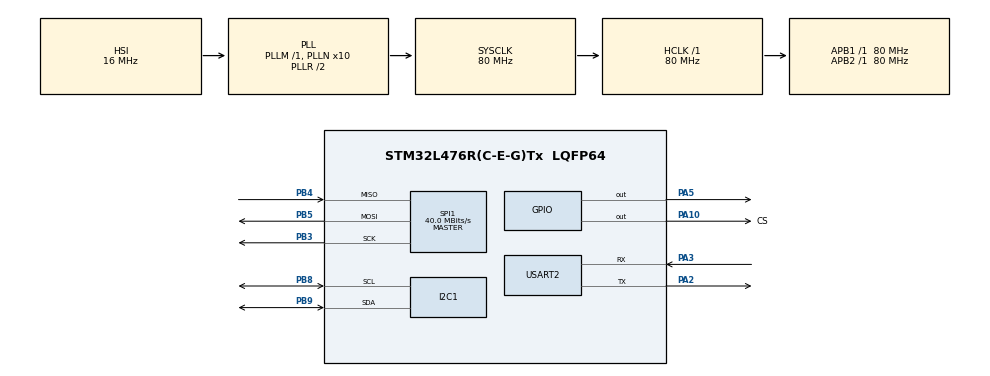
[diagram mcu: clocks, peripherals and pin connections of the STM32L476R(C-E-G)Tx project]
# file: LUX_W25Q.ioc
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Dma.I2C1_RX.0.Direction=DMA_PERIPH_TO_MEMORY
Dma.I2C1_RX.0.Instance=DMA1_Channel7
Dma.I2C1_RX.0.MemDataAlignment=DMA_MDATAALIGN_BYTE
Dma.I2C1_RX.0.MemInc=DMA_MINC_ENABLE
Dma.I2C1_RX.0.Mode=DMA_NORMAL
Dma.I2C1_RX.0.PeriphDataAlignment=DMA_PDATAALIGN_BYTE
Dma.I2C1_RX.0.PeriphInc=DMA_PINC_DISABLE
Dma.I2C1_RX.0.Priority=DMA_PRIORITY_LOW
Dma.I2C1_TX.1.Direction=DMA_MEMORY_TO_PERIPH
Dma.I2C1_TX.1.Instance=DMA1_Channel6
Dma.I2C1_TX.1.MemDataAlignment=DMA_MDATAALIGN_BYTE
Dma.I2C1_TX.1.MemInc=DMA_MINC_ENABLE
Dma.I2C1_TX.1.Mode=DMA_NORMAL
Dma.I2C1_TX.1.PeriphDataAlignment=DMA_PDATAALIGN_BYTE
Dma.I2C1_TX.1.PeriphInc=DMA_PINC_DISABLE
Dma.I2C1_TX.1.Priority=DMA_PRIORITY_LOW
Dma.Request0=I2C1_RX
Dma.Request1=I2C1_TX
I2C1.Timing=0x10909CEC
Mcu.Family=STM32L4
Mcu.Name=STM32L476R(C-E-G)Tx
Mcu.Package=LQFP64
NVIC.DMA1_Channel6_IRQn=true\:0\:0\:false\:false\:true\:false\:true
NVIC.DMA1_Channel7_IRQn=true\:0\:0\:false\:false\:true\:false\:true
NVIC.I2C1_ER_IRQn=true\:0\:0\:false\:false\:true\:true\:true
NVIC.I2C1_EV_IRQn=true\:0\:0\:false\:false\:true\:true\:true
NVIC.PriorityGroup=NVIC_PRIORITYGROUP_4
PA10.GPIO_Label=CS
PA10.Signal=GPIO_Output
PA2.Mode=Asynchronous
PA2.Signal=USART2_TX
PA3.Mode=Asynchronous
PA3.Signal=USART2_RX
PA5.Signal=GPIO_Output
PB3\ (JTDO-TRACESWO).Mode=Full_Duplex_Master
PB3\ (JTDO-TRACESWO).Signal=SPI1_SCK
PB4\ (NJTRST).Mode=Full_Duplex_Master
PB4\ (NJTRST).Signal=SPI1_MISO
PB5.Mode=Full_Duplex_Master
PB5.Signal=SPI1_MOSI
PB8.Mode=I2C
PB8.Signal=I2C1_SCL
PB9.Mode=I2C
PB9.Signal=I2C1_SDA
ProjectManager.HeapSize=0x200
ProjectManager.StackSize=0x400
ProjectManager.TargetToolchain=SW4STM32
RCC.ADCFreq_Value=64000000
RCC.AHBFreq_Value=80000000
RCC.APB1Freq_Value=80000000
RCC.APB1TimFreq_Value=80000000
RCC.APB2Freq_Value=80000000
RCC.APB2TimFreq_Value=80000000
RCC.CortexFreq_Value=80000000
RCC.HCLKFreq_Value=80000000
RCC.HSE_VALUE=8000000
RCC.HSI_VALUE=16000000
RCC.LSE_VALUE=32768
RCC.MSI_VALUE=4000000
RCC.PLLN=10
RCC.PLLSourceVirtual=RCC_PLLSOURCE_HSI
RCC.PREFETCH_ENABLE=1
RCC.SYSCLKFreq_VALUE=80000000
RCC.SYSCLKSource=RCC_SYSCLKSOURCE_PLLCLK
RCC.USBFreq_Value=64000000
RCC.VCOOutputFreq_Value=160000000
SPI1.CalculateBaudRate=40.0 MBits/s
SPI1.DataSize=SPI_DATASIZE_8BIT
SPI1.Direction=SPI_DIRECTION_2LINES
SPI1.Mode=SPI_MODE_MASTER
SPI1.VirtualType=VM_MASTER
USART2.VirtualMode-Asynchronous=VM_ASYNC
board=NUCLEO-L476RG

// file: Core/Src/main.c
/* USER CODE BEGIN Header */
/**
  ******************************************************************************
  * @file           : main.c
  * @brief          : Main program body
  ******************************************************************************
  * @attention
  *
  * <h2><center>&copy; Copyright (c) 2021 STMicroelectronics.
  * All rights reserved.</center></h2>
  *
  * This software component is licensed by ST under BSD 3-Clause license,
  * the "License"; You may not use this file except in compliance with the
  * License. You may obtain a copy of the License at:
  *                        opensource.org/licenses/BSD-3-Clause
  *
  ******************************************************************************
  */
/* USER CODE END Header */
#include "main.h"

/* USER CODE BEGIN Includes */
#include "W25Q.h"
#include "LUX.h"
/* USER CODE END Includes */

I2C_HandleTypeDef hi2c1;
DMA_HandleTypeDef hdma_i2c1_rx;
DMA_HandleTypeDef hdma_i2c1_tx;

SPI_HandleTypeDef hspi1;

UART_HandleTypeDef huart2;

void SystemClock_Config(void);
static void MX_GPIO_Init(void);
static void MX_DMA_Init(void);
static void MX_I2C1_Init(void);
static void MX_SPI1_Init(void);
static void MX_USART2_UART_Init(void);

int main(void)
{

  /* MCU Configuration--------------------------------------------------------*/

  /* Reset of all peripherals, Initializes the Flash interface and the Systick. */
  HAL_Init();

  /* Configure the system clock */
  SystemClock_Config();

  /* Initialize all configured peripherals */
  MX_GPIO_Init();
  MX_DMA_Init();
  MX_I2C1_Init();
  MX_SPI1_Init();
  MX_USART2_UART_Init();
  /* USER CODE BEGIN 2 */
  W25_Ini();
  //Erase();

  /* USER CODE END 2 */
  W25_Display();
  /* Infinite loop */
  while (1)
  {
	 // Get_I2C_Value();

  }
}

void SystemClock_Config(void)
{
  RCC_OscInitTypeDef RCC_OscInitStruct = {0};
  RCC_ClkInitTypeDef RCC_ClkInitStruct = {0};
  RCC_PeriphCLKInitTypeDef PeriphClkInit = {0};

  /** Initializes the RCC Oscillators according to the specified parameters
  * in the RCC_OscInitTypeDef structure.
  */
  RCC_OscInitStruct.OscillatorType = RCC_OSCILLATORTYPE_HSI;
  RCC_OscInitStruct.HSIState = RCC_HSI_ON;
  RCC_OscInitStruct.HSICalibrationValue = RCC_HSICALIBRATION_DEFAULT;
  RCC_OscInitStruct.PLL.PLLState = RCC_PLL_ON;
  RCC_OscInitStruct.PLL.PLLSource = RCC_PLLSOURCE_HSI;
  RCC_OscInitStruct.PLL.PLLM = 1;
  RCC_OscInitStruct.PLL.PLLN = 10;
  RCC_OscInitStruct.PLL.PLLP = RCC_PLLP_DIV7;
  RCC_OscInitStruct.PLL.PLLQ = RCC_PLLQ_DIV2;
  RCC_OscInitStruct.PLL.PLLR = RCC_PLLR_DIV2;
  if (HAL_RCC_OscConfig(&RCC_OscInitStruct) != HAL_OK)
  {
    Error_Handler();
  }
  /** Initializes the CPU, AHB and APB buses clocks
  */
  RCC_ClkInitStruct.ClockType = RCC_CLOCKTYPE_HCLK|RCC_CLOCKTYPE_SYSCLK
                              |RCC_CLOCKTYPE_PCLK1|RCC_CLOCKTYPE_PCLK2;
  RCC_ClkInitStruct.SYSCLKSource = RCC_SYSCLKSOURCE_PLLCLK;
  RCC_ClkInitStruct.AHBCLKDivider = RCC_SYSCLK_DIV1;
  RCC_ClkInitStruct.APB1CLKDivider = RCC_HCLK_DIV1;
  RCC_ClkInitStruct.APB2CLKDivider = RCC_HCLK_DIV1;

  if (HAL_RCC_ClockConfig(&RCC_ClkInitStruct, FLASH_LATENCY_4) != HAL_OK)
  {
    Error_Handler();
  }
  PeriphClkInit.PeriphClockSelection = RCC_PERIPHCLK_USART2|RCC_PERIPHCLK_I2C1;
  PeriphClkInit.Usart2ClockSelection = RCC_USART2CLKSOURCE_PCLK1;
  PeriphClkInit.I2c1ClockSelection = RCC_I2C1CLKSOURCE_PCLK1;
  if (HAL_RCCEx_PeriphCLKConfig(&PeriphClkInit) != HAL_OK)
  {
    Error_Handler();
  }
  /** Configure the main internal regulator output voltage
  */
  if (HAL_PWREx_ControlVoltageScaling(PWR_REGULATOR_VOLTAGE_SCALE1) != HAL_OK)
  {
    Error_Handler();
  }
}

static void MX_I2C1_Init(void)
{

  hi2c1.Instance = I2C1;
  hi2c1.Init.Timing = 0x10909CEC;
  hi2c1.Init.OwnAddress1 = 0;
  hi2c1.Init.AddressingMode = I2C_ADDRESSINGMODE_7BIT;
  hi2c1.Init.DualAddressMode = I2C_DUALADDRESS_DISABLE;
  hi2c1.Init.OwnAddress2 = 0;
  hi2c1.Init.OwnAddress2Masks = I2C_OA2_NOMASK;
  hi2c1.Init.GeneralCallMode = I2C_GENERALCALL_DISABLE;
  hi2c1.Init.NoStretchMode = I2C_NOSTRETCH_DISABLE;
  if (HAL_I2C_Init(&hi2c1) != HAL_OK)
  {
    Error_Handler();
  }
  /** Configure Analogue filter
  */
  if (HAL_I2CEx_ConfigAnalogFilter(&hi2c1, I2C_ANALOGFILTER_ENABLE) != HAL_OK)
  {
    Error_Handler();
  }
  /** Configure Digital filter
  */
  if (HAL_I2CEx_ConfigDigitalFilter(&hi2c1, 0) != HAL_OK)
  {
    Error_Handler();
  }

}

static void MX_SPI1_Init(void)
{

  /* SPI1 parameter configuration*/
  hspi1.Instance = SPI1;
  hspi1.Init.Mode = SPI_MODE_MASTER;
  hspi1.Init.Direction = SPI_DIRECTION_2LINES;
  hspi1.Init.DataSize = SPI_DATASIZE_8BIT;
  hspi1.Init.CLKPolarity = SPI_POLARITY_LOW;
  hspi1.Init.CLKPhase = SPI_PHASE_1EDGE;
  hspi1.Init.NSS = SPI_NSS_SOFT;
  hspi1.Init.BaudRatePrescaler = SPI_BAUDRATEPRESCALER_2;
  hspi1.Init.FirstBit = SPI_FIRSTBIT_MSB;
  hspi1.Init.TIMode = SPI_TIMODE_DISABLE;
  hspi1.Init.CRCCalculation = SPI_CRCCALCULATION_DISABLE;
  hspi1.Init.CRCPolynomial = 7;
  hspi1.Init.CRCLength = SPI_CRC_LENGTH_DATASIZE;
  hspi1.Init.NSSPMode = SPI_NSS_PULSE_ENABLE;
  if (HAL_SPI_Init(&hspi1) != HAL_OK)
  {
    Error_Handler();
  }

}

static void MX_USART2_UART_Init(void)
{

  huart2.Instance = USART2;
  huart2.Init.BaudRate = 115200;
  huart2.Init.WordLength = UART_WORDLENGTH_8B;
  huart2.Init.StopBits = UART_STOPBITS_1;
  huart2.Init.Parity = UART_PARITY_NONE;
  huart2.Init.Mode = UART_MODE_TX_RX;
  huart2.Init.HwFlowCtl = UART_HWCONTROL_NONE;
  huart2.Init.OverSampling = UART_OVERSAMPLING_16;
  huart2.Init.OneBitSampling = UART_ONE_BIT_SAMPLE_DISABLE;
  huart2.AdvancedInit.AdvFeatureInit = UART_ADVFEATURE_NO_INIT;
  if (HAL_UART_Init(&huart2) != HAL_OK)
  {
    Error_Handler();
  }

}

static void MX_DMA_Init(void)
{

  /* DMA controller clock enable */
  __HAL_RCC_DMA1_CLK_ENABLE();

  /* DMA interrupt init */
  /* DMA1_Channel6_IRQn interrupt configuration */
  HAL_NVIC_SetPriority(DMA1_Channel6_IRQn, 0, 0);
  HAL_NVIC_EnableIRQ(DMA1_Channel6_IRQn);
  /* DMA1_Channel7_IRQn interrupt configuration */
  HAL_NVIC_SetPriority(DMA1_Channel7_IRQn, 0, 0);
  HAL_NVIC_EnableIRQ(DMA1_Channel7_IRQn);

}

static void MX_GPIO_Init(void)
{
  GPIO_InitTypeDef GPIO_InitStruct = {0};

  /* GPIO Ports Clock Enable */
  __HAL_RCC_GPIOA_CLK_ENABLE();
  __HAL_RCC_GPIOB_CLK_ENABLE();

  /*Configure GPIO pin Output Level */
  HAL_GPIO_WritePin(GPIOA, GPIO_PIN_5|CS_Pin, GPIO_PIN_RESET);

  /*Configure GPIO pins : PA5 CS_Pin */
  GPIO_InitStruct.Pin = GPIO_PIN_5|CS_Pin;
  GPIO_InitStruct.Mode = GPIO_MODE_OUTPUT_PP;
  GPIO_InitStruct.Pull = GPIO_NOPULL;
  GPIO_InitStruct.Speed = GPIO_SPEED_FREQ_LOW;
  HAL_GPIO_Init(GPIOA, &GPIO_InitStruct);

}

void Error_Handler(void)
{
  __disable_irq();
  while (1)
  {
  }
}

/************************ (C) COPYRIGHT STMicroelectronics *****END OF FILE****/
